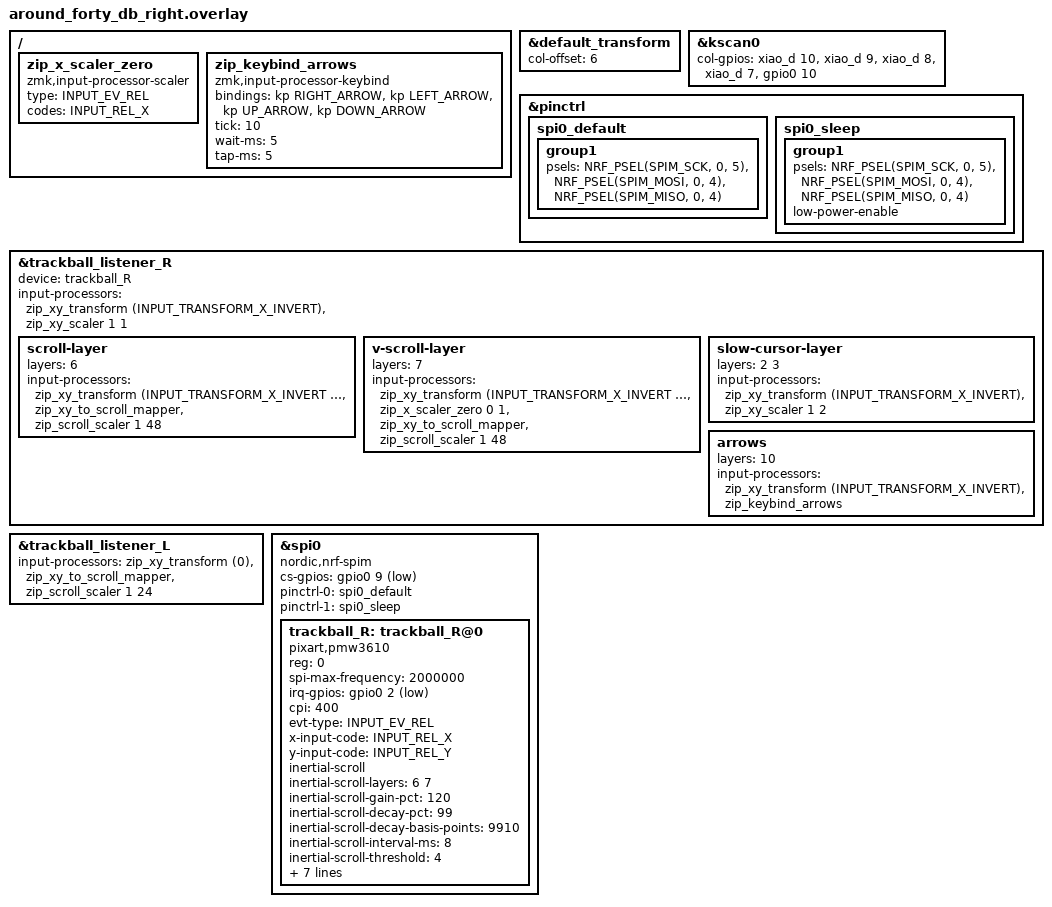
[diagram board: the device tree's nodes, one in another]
#include "around_forty_db.dtsi"
#include <dt-bindings/zmk/keys.h>
#include <dt-bindings/zmk/pointing.h>
#include <dt-bindings/zmk/input_transform.h>
#include <input/processors.dtsi>
#include <zephyr/dt-bindings/input/input-event-codes.h>


&default_transform {
    col-offset = <6>;
};

&kscan0 {
        col-gpios
            = <&xiao_d 10 GPIO_ACTIVE_HIGH>
            , <&xiao_d 9 GPIO_ACTIVE_HIGH>
            , <&xiao_d 8 GPIO_ACTIVE_HIGH>
            , <&xiao_d 7 GPIO_ACTIVE_HIGH>
            , <&gpio0 10 GPIO_ACTIVE_HIGH>
            ;
};


&pinctrl {
    spi0_default: spi0_default {
        group1 {
            psels = <NRF_PSEL(SPIM_SCK, 0, 5)>,
                    <NRF_PSEL(SPIM_MOSI, 0, 4)>,
                    <NRF_PSEL(SPIM_MISO, 0, 4)>;
        };
    };

    spi0_sleep: spi0_sleep {
        group1 {
            psels = <NRF_PSEL(SPIM_SCK, 0, 5)>,
                    <NRF_PSEL(SPIM_MOSI, 0, 4)>,
                    <NRF_PSEL(SPIM_MISO, 0, 4)>;
            low-power-enable;
        };
    };
};

/ {
    /* X軸の移動量を強制的に0にするプロセッサ（垂直スクロール限定モード用） */
    zip_x_scaler_zero: zip_x_scaler_zero {
        compatible = "zmk,input-processor-scaler";
        #input-processor-cells = <2>;
        type = <INPUT_EV_REL>;
        codes = <INPUT_REL_X>;
    };

    zip_keybind_arrows: zip_keybind_arrows {
        compatible = "zmk,input-processor-keybind";
        #input-processor-cells = <0>;
        bindings =
            <&kp RIGHT_ARROW>,
            <&kp LEFT_ARROW>,
            <&kp UP_ARROW>,
            <&kp DOWN_ARROW>;
        tick = <10>;
        wait-ms = <5>;
        tap-ms = <5>;
    };
};

&trackball_listener_R {
    status = "okay";
    device = <&trackball_R>;

    // 通常モード
    input-processors =
        <&zip_xy_transform (INPUT_TRANSFORM_X_INVERT)>,
        <&zip_xy_scaler 1 1>;

    // スクロールレイヤー（Layer 6）
    scroll-layer {
        layers = <6>;
        input-processors =
            <&zip_xy_transform (INPUT_TRANSFORM_X_INVERT | INPUT_TRANSFORM_Y_INVERT)>,
            <&zip_xy_to_scroll_mapper>,
            <&zip_scroll_scaler 1 48>;
    };

    // 縦専用スクロールレイヤー（Layer 7）
    v-scroll-layer {
        layers = <7>;
        input-processors =
            <&zip_xy_transform (INPUT_TRANSFORM_X_INVERT | INPUT_TRANSFORM_Y_INVERT)>,
            <&zip_x_scaler_zero 0 1>,
            <&zip_xy_to_scroll_mapper>,
            <&zip_scroll_scaler 1 48>;
    };

    // スローカーソルレイヤー（Layer 2, 3）
    slow-cursor-layer {
        layers = <2 3>;
        input-processors =
            <&zip_xy_transform (INPUT_TRANSFORM_X_INVERT)>,
            <&zip_xy_scaler 1 2>;
    };

    // 矢印キーレイヤー（Layer 10）
    arrows {
        layers = <10>;
        input-processors =
            <&zip_xy_transform (INPUT_TRANSFORM_X_INVERT)>,
            <&zip_keybind_arrows>;
    };
};

&trackball_listener_L {
    status = "okay";

    // 左手トラックボールはスクロール用
    input-processors =
        <&zip_xy_transform (0)>,
        <&zip_xy_to_scroll_mapper>,
        <&zip_scroll_scaler 1 24>;
};

&spi0 {
    status = "okay";
    cs-gpios = <&gpio0 9 GPIO_ACTIVE_LOW>;
    pinctrl-0 = <&spi0_default>;
    pinctrl-1 = <&spi0_sleep>;
    pinctrl-names = "default", "sleep";
    compatible = "nordic,nrf-spim";

    trackball_R: trackball_R@0 {
        status = "okay";
        compatible = "pixart,pmw3610";
        reg = <0>;
        spi-max-frequency = <2000000>;
        irq-gpios = <&gpio0 2 (GPIO_ACTIVE_LOW | GPIO_PULL_UP)>;
        cpi = <400>;
        evt-type = <INPUT_EV_REL>;
        x-input-code = <INPUT_REL_X>;
        y-input-code = <INPUT_REL_Y>;
        inertial-scroll;
        inertial-scroll-layers = <6 7>;
        inertial-scroll-gain-pct = <120>;
        inertial-scroll-decay-pct = <99>;
        inertial-scroll-decay-basis-points = <9910>;
        inertial-scroll-interval-ms = <8>;
        inertial-scroll-threshold = <4>;
        inertial-scroll-max-velocity = <28>;
        inertial-scroll-max-duration-ms = <1600>;
        motion-threshold = <0>;
        low-speed-stabilizer;
        low-speed-stabilizer-threshold = <1>;
        low-speed-stabilizer-timeout-ms = <30>;
        force-awake;
    };
};
